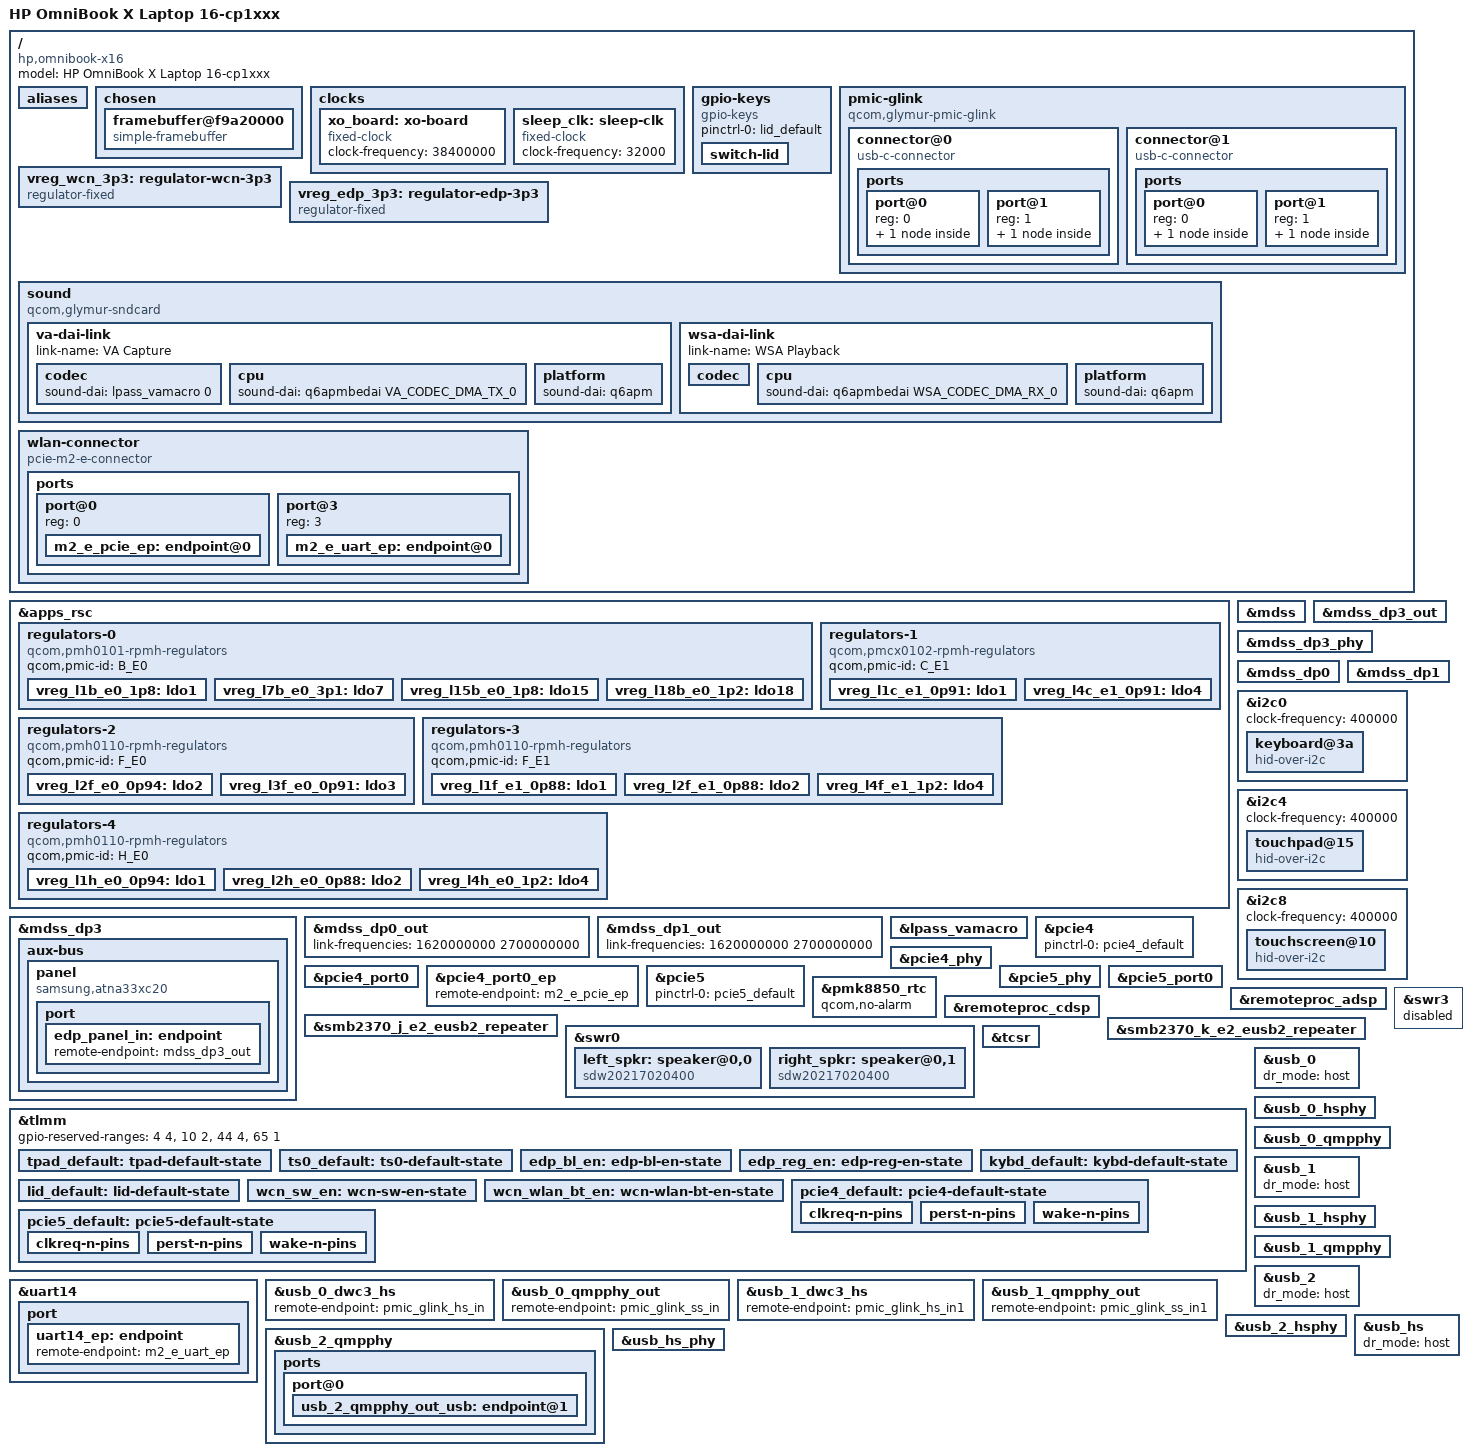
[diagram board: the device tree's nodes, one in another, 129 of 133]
// SPDX-License-Identifier: BSD-3-Clause
/*
 * HP OmniBook X Laptop 16-cp1xxx (Snapdragon X2 Elite, 12-core "Mahua")
 *
 * Community test device tree, built up in stages and boot-tested on one
 * laptop (board 8F46). Most hardware works; see the notes at the end and the
 * "Stage N" comments for what each block does and how it was verified.
 *
 * Derived from glymur-hp-elitebook-x-g2q.dts (board wiring) on top of
 * mahua.dtsi (SoC), following how mahua-crd.dts adapts Glymur to Mahua.
 *
 * Markers:
 *   VERIFIED   - confirmed from this laptop's ACPI tables or by a test boot
 *   DONOR      - copied from the EliteBook X G2q, NOT verified on this laptop
 *   GUESS      - best effort
 *   TODO       - unknown, must be found before it can be enabled
 */

/dts-v1/;

#include "mahua.dtsi"

#include "pmcx0102.dtsi"
#include "pmh0101.dtsi"
#include "pmh0110-glymur.dtsi"
#include "pmh0104-glymur.dtsi"
#include "pmk8850.dtsi"
#include "smb2370.dtsi"

#include <dt-bindings/gpio/gpio.h>
#include <dt-bindings/input/gpio-keys.h>
#include <dt-bindings/input/input.h>
#include <dt-bindings/interrupt-controller/irq.h>
#include <dt-bindings/regulator/qcom,rpmh-regulator.h>
#include <dt-bindings/sound/qcom,q6dsp-lpass-ports.h>

/* Same PMIC removals that mahua-crd.dts makes for the 12-core part */
/delete-node/ &pmcx0102_d_e0;
/delete-node/ &pmcx0102_d0_thermal;
/delete-node/ &pmh0104_i_e0;
/delete-node/ &pmh0104_i0_thermal;
/delete-node/ &pmh0104_j_e0;
/delete-node/ &pmh0104_j0_thermal;

/ {
	model = "HP OmniBook X Laptop 16-cp1xxx";
	compatible = "hp,omnibook-x16", "qcom,mahua";

	aliases {
		i2c0 = &i2c0;
		i2c4 = &i2c4;
		i2c8 = &i2c8;

		serial0 = &uart21;	/* debug UART, as on the other Glymur/Mahua laptops; fixes "Invalid line -19" */
		serial1 = &uart14;	/* DONOR; geni UART refuses to probe without an alias */
	};

	/*
	 * UEFI framebuffer, described here so simpledrm holds the display's
	 * power rails. Without a consumer, rpmhpd drops MMCX/MXC at sync_state
	 * and the screen goes black (theory from test boots 2 and 3, Oct 19).
	 * reg/width/height/stride VERIFIED from BOOTFB in /proc/iomem and
	 * /sys/class/graphics/fb0 in ACPI mode (1920x1200, stride 7680).
	 * Rail levels (nom) are a GUESS; supplies are the DONOR eDP PHY supplies.
	 * A /chosen framebuffer also stops sysfb from registering a second one.
	 */
	chosen {
		#address-cells = <2>;
		#size-cells = <2>;
		ranges;

		framebuffer@f9a20000 {
			compatible = "simple-framebuffer";
			reg = <0x0 0xf9a20000 0x0 0x8ca000>;
			width = <1920>;
			height = <1200>;
			stride = <(1920 * 4)>;
			format = "x8r8g8b8";

			power-domains = <&rpmhpd RPMHPD_MMCX>,
					<&rpmhpd RPMHPD_MXC>;
			required-opps = <&rpmhpd_opp_nom>,
					<&rpmhpd_opp_nom>;

			vdda-phy-supply = <&vreg_l2f_e1_0p88>;
			vdda-pll-supply = <&vreg_l4f_e1_1p2>;
		};
	};

	clocks {
		xo_board: xo-board {
			compatible = "fixed-clock";
			clock-frequency = <38400000>;
			#clock-cells = <0>;
		};

		sleep_clk: sleep-clk {
			compatible = "fixed-clock";
			clock-frequency = <32000>;
			#clock-cells = <0>;
		};
	};

	/* VERIFIED: ACPI LIDR uses TLMM pin 92 (0x5C), same as the donor */
	gpio-keys {
		compatible = "gpio-keys";

		pinctrl-0 = <&lid_default>;
		pinctrl-names = "default";

		switch-lid {
			label = "lid";
			gpios = <&tlmm 92 GPIO_ACTIVE_LOW>;
			linux,input-type = <EV_SW>;
			linux,code = <SW_LID>;
			wakeup-source;
			wakeup-event-action = <EV_ACT_DEASSERTED>;
		};
	};

	/*
	 * Stage 4. On Glymur/Mahua pmic-glink talks to the SoCCP (not the ADSP).
	 * VERIFIED: the PMIC_RTR_SOCCP_APPS rpmsg channel exists in DT mode, and
	 * the DSDT has PMGK (QCOM0F8E). Node layout DONOR.
	 * GUESS: firmware connector 0 = usb_0 (left back), 1 = usb_1 (left front),
	 * same order as the DSDT URS0/URS1.
	 */
	pmic-glink {
		compatible = "qcom,glymur-pmic-glink",
			     "qcom,pmic-glink";
		#address-cells = <1>;
		#size-cells = <0>;

		/* Left back port (usb_0) */
		connector@0 {
			compatible = "usb-c-connector";
			reg = <0>;
			power-role = "dual";
			data-role = "dual";

			ports {
				#address-cells = <1>;
				#size-cells = <0>;

				port@0 {
					reg = <0>;

					pmic_glink_hs_in: endpoint {
						remote-endpoint = <&usb_0_dwc3_hs>;
					};
				};

				port@1 {
					reg = <1>;

					pmic_glink_ss_in: endpoint {
						remote-endpoint = <&usb_0_qmpphy_out>;
					};
				};
			};
		};

		/* Left front port (usb_1) */
		connector@1 {
			compatible = "usb-c-connector";
			reg = <1>;
			power-role = "dual";
			data-role = "dual";

			ports {
				#address-cells = <1>;
				#size-cells = <0>;

				port@0 {
					reg = <0>;

					pmic_glink_hs_in1: endpoint {
						remote-endpoint = <&usb_1_dwc3_hs>;
					};
				};

				port@1 {
					reg = <1>;

					pmic_glink_ss_in1: endpoint {
						remote-endpoint = <&usb_1_qmpphy_out>;
					};
				};
			};
		};
	};

	/*
	 * Wi-Fi (QCC2072, PCI 17cb:1112). DONOR pins: all five Glymur boards
	 * in-tree agree on gpio94 (3.3 V switch) and gpio116/117 (BT/WLAN
	 * enable). The ACPI tables do not switch any Wi-Fi power. There is no
	 * pwrseq driver for the QCC2072, so it is described as an M.2 key E
	 * slot, like the Zenbook A16. Bluetooth (port@3 -> uart14) is left
	 * out for now.
	 */
	vreg_wcn_3p3: regulator-wcn-3p3 {
		compatible = "regulator-fixed";

		regulator-name = "VREG_WCN_3P3";
		regulator-min-microvolt = <3300000>;
		regulator-max-microvolt = <3300000>;

		gpio = <&tlmm 94 GPIO_ACTIVE_HIGH>;	/* DONOR */
		enable-active-high;

		pinctrl-0 = <&wcn_sw_en>;
		pinctrl-names = "default";

		regulator-boot-on;
	};

	/*
	 * Panel 3.3 V switch. DONOR: gpio70 on all five Glymur/Mahua boards
	 * upstream (CRD, EliteBook X G2q, Yoga Slim 7x, Zenbook A14/A16).
	 */
	vreg_edp_3p3: regulator-edp-3p3 {
		compatible = "regulator-fixed";

		regulator-name = "VREG_EDP_3P3";
		regulator-min-microvolt = <3300000>;
		regulator-max-microvolt = <3300000>;

		gpio = <&tlmm 70 GPIO_ACTIVE_HIGH>;	/* DONOR */
		enable-active-high;

		pinctrl-0 = <&edp_reg_en>;
		pinctrl-names = "default";

		regulator-boot-on;
	};

	/*
	 * Speakers + built-in mics, copied from the donor (DONOR). ACPI only
	 * describes the headphone jack (a Qualcomm SDCA codec, vendor 0x0217),
	 * so the speaker/mic wiring here is NOT verified for this board.
	 * model = "GLYMUR-CRD" (TEMP) so the kernel loads the installed
	 * qcom/glymur/GLYMUR-CRD-tplg.bin and ALSA uses the GLYMUR-CRD UCM.
	 * Both expect exactly these two links (WSA RX0 + VA TX0).
	 * Stage 8c: only TWO speakers (both on swr0, GUESS from boots 13-15 +
	 * Windows 2-ch endpoint + spec sites). ALSA must use a two-speaker UCM
	 * (/usr/share/alsa/ucm2/conf.d/glymur/HP-...-8F46.conf), not GLYMUR-CRD.
	 */
	sound {
		compatible = "qcom,glymur-sndcard";
		model = "GLYMUR-CRD";

		audio-routing = "SpkrLeft IN", "WSA WSA_SPK1 OUT",
				"SpkrRight IN", "WSA WSA_SPK2 OUT",
				"VA DMIC0", "vdd-micb",
				"VA DMIC1", "vdd-micb";

		va-dai-link {
			link-name = "VA Capture";

			codec {
				sound-dai = <&lpass_vamacro 0>;
			};

			cpu {
				sound-dai = <&q6apmbedai VA_CODEC_DMA_TX_0>;
			};

			platform {
				sound-dai = <&q6apm>;
			};
		};

		wsa-dai-link {
			link-name = "WSA Playback";

			codec {
				sound-dai = <&left_spkr>, <&right_spkr>,
					    <&swr0 0>, <&lpass_wsamacro 0>;
			};

			cpu {
				sound-dai = <&q6apmbedai WSA_CODEC_DMA_RX_0>;
			};

			platform {
				sound-dai = <&q6apm>;
			};
		};
	};

	wlan-connector {
		compatible = "pcie-m2-e-connector";
		vpcie3v3-supply = <&vreg_wcn_3p3>;
		vpcie1v8-supply = <&vreg_l15b_e0_1p8>;	/* DONOR */

		w-disable1-gpios = <&tlmm 117 GPIO_ACTIVE_LOW>;	/* DONOR (WLAN) */
		w-disable2-gpios = <&tlmm 116 GPIO_ACTIVE_LOW>;	/* DONOR (BT) */

		pinctrl-0 = <&wcn_wlan_bt_en>;
		pinctrl-names = "default";

		ports {
			#address-cells = <1>;
			#size-cells = <0>;

			port@0 {
				reg = <0>;
				#address-cells = <1>;
				#size-cells = <0>;

				m2_e_pcie_ep: endpoint@0 {
					reg = <0>;
					remote-endpoint = <&pcie4_port0_ep>;
				};
			};

			/*
			 * Bluetooth UART. VERIFIED from ACPI: BTH0 (QCOM0F6B) sits on
			 * UR15 = 0x00a98000 = uart14, 115200 baud + RTS/CTS, enable
			 * GPIO 0x74 = 116 (= w-disable2 above). Needs patched
			 * pwrseq-pcie-m2 + hci_qca (QCC2072 not upstream in 7.3).
			 */
			port@3 {
				reg = <3>;
				#address-cells = <1>;
				#size-cells = <0>;

				m2_e_uart_ep: endpoint@0 {
					reg = <0>;
					remote-endpoint = <&uart14_ep>;
				};
			};
		};
	};
};

&apps_rsc {
	/* DONOR: PMIC regulators, needed by the PCIe PHY and USB PHYs */
	regulators-0 {
		compatible = "qcom,pmh0101-rpmh-regulators";
		qcom,pmic-id = "B_E0";

		vreg_l1b_e0_1p8: ldo1 {
			regulator-name = "vreg_l1b_e0_1p8";
			regulator-min-microvolt = <1800000>;
			regulator-max-microvolt = <1800000>;
			regulator-initial-mode = <RPMH_REGULATOR_MODE_HPM>;
		};

		vreg_l7b_e0_3p1: ldo7 {
			regulator-name = "vreg_l7b_e0_3p1";
			regulator-min-microvolt = <3072000>;
			regulator-max-microvolt = <3072000>;
			regulator-initial-mode = <RPMH_REGULATOR_MODE_HPM>;
		};

		vreg_l15b_e0_1p8: ldo15 {
			regulator-name = "vreg_l15b_e0_1p8";
			regulator-min-microvolt = <1800000>;
			regulator-max-microvolt = <1800000>;
			regulator-initial-mode = <RPMH_REGULATOR_MODE_HPM>;
		};

		vreg_l18b_e0_1p2: ldo18 {
			regulator-name = "vreg_l18b_e0_1p2";
			regulator-min-microvolt = <1200000>;
			regulator-max-microvolt = <1200000>;
			regulator-initial-mode = <RPMH_REGULATOR_MODE_HPM>;
		};
	};

	regulators-1 {
		compatible = "qcom,pmcx0102-rpmh-regulators";
		qcom,pmic-id = "C_E1";

		vreg_l1c_e1_0p91: ldo1 {
			regulator-name = "vreg_l1c_e1_0p91";
			regulator-min-microvolt = <912000>;
			regulator-max-microvolt = <912000>;
			regulator-initial-mode = <RPMH_REGULATOR_MODE_HPM>;
		};

		/*
		 * Stage 10: usb_2 (USB-A) PHY rail. VERIFIED in this laptop's DSDT PEP
		 * package for \_SB.USB2 (PPP_RESOURCE_ID_LDO4_C_E1). Voltage DONOR from
		 * the Yoga Slim 7x / Zenbook A16 (912 mV; GLYMUR-CRD names it 0p72 but
		 * also names l3f_e0 0p72, which the HP donor runs at 912 mV).
		 */
		vreg_l4c_e1_0p91: ldo4 {
			regulator-name = "vreg_l4c_e1_0p91";
			regulator-min-microvolt = <912000>;
			regulator-max-microvolt = <912000>;
			regulator-initial-mode = <RPMH_REGULATOR_MODE_HPM>;
		};
	};

	regulators-2 {
		compatible = "qcom,pmh0110-rpmh-regulators";
		qcom,pmic-id = "F_E0";

		vreg_l2f_e0_0p94: ldo2 {
			regulator-name = "vreg_l2f_e0_0p94";
			regulator-min-microvolt = <936000>;
			regulator-max-microvolt = <936000>;
			regulator-initial-mode = <RPMH_REGULATOR_MODE_HPM>;
		};

		vreg_l3f_e0_0p91: ldo3 {
			regulator-name = "vreg_l3f_e0_0p91";
			regulator-min-microvolt = <912000>;
			regulator-max-microvolt = <912000>;
			regulator-initial-mode = <RPMH_REGULATOR_MODE_HPM>;
		};
	};

	regulators-3 {
		compatible = "qcom,pmh0110-rpmh-regulators";
		qcom,pmic-id = "F_E1";

		vreg_l1f_e1_0p88: ldo1 {
			regulator-name = "vreg_l1f_e1_0p88";
			regulator-min-microvolt = <880000>;
			regulator-max-microvolt = <880000>;
			regulator-initial-mode = <RPMH_REGULATOR_MODE_HPM>;
		};

		vreg_l2f_e1_0p88: ldo2 {
			regulator-name = "vreg_l2f_e1_0p88";
			regulator-min-microvolt = <880000>;
			regulator-max-microvolt = <880000>;
			regulator-initial-mode = <RPMH_REGULATOR_MODE_HPM>;
		};

		vreg_l4f_e1_1p2: ldo4 {
			regulator-name = "vreg_l4f_e1_1p2";
			regulator-min-microvolt = <1200000>;
			regulator-max-microvolt = <1200000>;
			regulator-initial-mode = <RPMH_REGULATOR_MODE_HPM>;
		};
	};

	regulators-4 {
		compatible = "qcom,pmh0110-rpmh-regulators";
		qcom,pmic-id = "H_E0";

		vreg_l1h_e0_0p94: ldo1 {
			regulator-name = "vreg_l1h_e0_0p94";
			regulator-min-microvolt = <936000>;
			regulator-max-microvolt = <936000>;
			regulator-initial-mode = <RPMH_REGULATOR_MODE_HPM>;
		};

		vreg_l2h_e0_0p88: ldo2 {
			regulator-name = "vreg_l2h_e0_0p88";
			regulator-min-microvolt = <880000>;
			regulator-max-microvolt = <880000>;
			regulator-initial-mode = <RPMH_REGULATOR_MODE_HPM>;
		};

		vreg_l4h_e0_1p2: ldo4 {
			regulator-name = "vreg_l4h_e0_1p2";
			regulator-min-microvolt = <1200000>;
			regulator-max-microvolt = <1200000>;
			regulator-initial-mode = <RPMH_REGULATOR_MODE_HPM>;
		};
	};
};

/*
 * Stage 11: display driver (msm DRM) on the internal eDP panel (DP3).
 * dispcc is enabled again (it is on by default in glymur.dtsi; stages 1-10
 * had it disabled). The /chosen simple-framebuffer stays as a fallback:
 * msm removes it when it takes over, simpledrm keeps working if msm fails.
 * USB-C DisplayPort (mdss_dp0/dp1) is added in stage 15 (below &mdss_dp3_phy).
 *
 * Panel: SDC 0x4214 OLED 1920x1200 (VERIFIED from Windows WmiMonitorID).
 * "samsung,atna33xc20" is the generic driver for Samsung OLED eDP panels
 * (backlight over DP AUX); the exact model name is unknown, so no specific
 * compatible. enable-gpios 18 / supply gpio70 = DONOR (all Glymur boards
 * agree). Link rates / 4 lanes = DONOR.
 */
&mdss {
	status = "okay";
};

&mdss_dp3 {
	/delete-property/ #sound-dai-cells;

	status = "okay";

	aux-bus {
		panel {
			compatible = "samsung,atna33xc20";	/* GUESS: generic */
			enable-gpios = <&tlmm 18 GPIO_ACTIVE_HIGH>;	/* DONOR */
			power-supply = <&vreg_edp_3p3>;

			pinctrl-0 = <&edp_bl_en>;
			pinctrl-names = "default";

			port {
				edp_panel_in: endpoint {
					remote-endpoint = <&mdss_dp3_out>;
				};
			};
		};
	};
};

&mdss_dp3_out {
	data-lanes = <0 1 2 3>;
	link-frequencies = /bits/ 64 <1620000000 2700000000 5400000000 8100000000>;

	remote-endpoint = <&edp_panel_in>;
};

&mdss_dp3_phy {
	vdda-phy-supply = <&vreg_l2f_e1_0p88>;
	vdda-pll-supply = <&vreg_l4f_e1_1p2>;

	status = "okay";
};

/*
 * Stage 15: DisplayPort alt mode on the two USB-C ports. DONOR (EliteBook X
 * G2q): glymur.dtsi already wires mdss_dp0 -> usb_0_qmpphy (left back) and
 * mdss_dp1 -> usb_1_qmpphy (left front); pmic_glink_altmode reports HPD and
 * the pin assignment through the connectors. Link rates DONOR. Whether HP
 * wired DP to these ports is not checked from ACPI, but both ports give a 1080p60
 * picture through a USB-C hub with HDMI output (VERIFIED).
 * At HBR2 (5.4 Gbps) link training passed but the stream ran at exactly 30 Hz
 * instead of 60 (measured vblanks) -> no picture. Capped at HBR (2.7 Gbps): 60 Hz,
 * picture OK (VERIFIED). Likely cause: the QMP v8 VCO_DIV value for 5400 in
 * phy-qcom-qmp-combo.c (0x4; the Glymur eDP PHY uses 0x2). Remove the cap once
 * that is fixed. With the cap: 2 lanes x HBR, enough for 1080p60, not 1440p60/4K60.
 */
&mdss_dp0 {
	status = "okay";
};

&mdss_dp0_out {
	link-frequencies = /bits/ 64 <1620000000 2700000000>; /* HBR max: HBR2 runs at half rate, see above */
};

&mdss_dp1 {
	status = "okay";
};

&mdss_dp1_out {
	link-frequencies = /bits/ 64 <1620000000 2700000000>; /* HBR max: HBR2 runs at half rate, see above */
};

/*
 * Keyboard: bus i2c@b80000, address 0x3a and HID descriptor address 1 are
 * VERIFIED from this laptop's DSDT (QTEC0001 on ACPI I2C1, 400 kHz).
 * Interrupt gpio67 (from the donor) is VERIFIED by test boot 3 (Oct 19):
 * typing blind at the tty1 login prompt produced login attempts in auth.log.
 */
/*
 * GPU/GMU: left enabled (glymur.dtsi has no status). With the stock 7.3 kernel the
 * screen is corrupted under hardware rendering: msm reports the full 4-slice GMEM, but
 * Mahua's X2-85 has 3 slices. FIX VERIFIED (Oct 22): "drm/msm: Mahua GPU support" v1.
 * Patch 5 goes into mahua.dtsi (gpu "qcom,adreno-44060000", gmu "qcom,adreno-gmu-x285.0")
 * and REQUIRES a msm.ko with patch 3 (catalog entry 0x44060000, 15.75 MB GMEM); with the
 * stock msm.ko that DTB has no GPU. Without either patch, the Mesa workaround (FD_MESA_DEBUG/
 * TU_DEBUG=sysmem, VERIFIED boot 22) avoids the corruption. See gpu/ in the repo.
 */

&i2c0 {
	clock-frequency = <400000>;

	status = "okay";

	keyboard@3a {
		compatible = "hid-over-i2c";
		reg = <0x3a>;

		hid-descr-addr = <0x1>;
		interrupts-extended = <&tlmm 67 IRQ_TYPE_LEVEL_LOW>; /* VERIFIED */

		pinctrl-0 = <&kybd_default>;
		pinctrl-names = "default";

		wakeup-source;
	};
};

/*
 * Touchpad: bus i2c@b90000, address 0x15 and HID descriptor address 1 are
 * VERIFIED (ELAN0189 on ACPI I2C5, 400 kHz). The interrupt pin is NOT
 * verified: ACPI says 896 in an undecoded numbering, but both the
 * x1-hp-omnibook-x14.dtsi and glymur-hp-elitebook-x-g2q.dts use gpio3 for
 * their touchpads (the X14 also uses address 0x15), so gpio3 is the guess.
 */
&i2c4 {
	clock-frequency = <400000>;

	status = "okay";

	touchpad@15 {
		compatible = "hid-over-i2c";
		reg = <0x15>;

		hid-descr-addr = <0x1>;
		interrupts-extended = <&tlmm 3 IRQ_TYPE_LEVEL_LOW>; /* GUESS */

		pinctrl-0 = <&tpad_default>;
		pinctrl-names = "default";

		wakeup-source;
	};
};

/*
 * Touchscreen (stage 14): ACPI TSC1 = ELAN2513 on I2C9 (QUP_1_SE_0, base
 * 0x00a80000 = i2c8), address 0x10, 400 kHz, HID descriptor address 1,
 * GpioInt pin 51 level active-low. VERIFIED from this laptop's DSDT (decoded
 * by hand); TSC1 _STA is on because \_SB.SKID = 1. Matches the donor node
 * exactly. VERIFIED Oct 21: ELAN 04F3:44BF probes on 8-0010 and touch works.
 */
&i2c8 {
	clock-frequency = <400000>;

	status = "okay";

	touchscreen@10 {
		compatible = "hid-over-i2c";
		reg = <0x10>;

		hid-descr-addr = <0x1>;
		interrupts-extended = <&tlmm 51 IRQ_TYPE_LEVEL_LOW>;

		post-power-on-delay-ms = <200>;	/* DONOR */

		pinctrl-0 = <&ts0_default>;
		pinctrl-names = "default";
	};
};

/* Built-in digital mics on DMIC0/1 (DONOR) */
&lpass_vamacro {
	vdd-micb-supply = <&vreg_l1b_e0_1p8>;

	pinctrl-0 = <&dmic01_default>;
	pinctrl-names = "default";

	qcom,dmic-sample-rate = <4800000>;
};

/* Wi-Fi (ACPI shows it on PCIe domain 4, matching the donors' pcie4) */
&pcie4 {
	pinctrl-0 = <&pcie4_default>;
	pinctrl-names = "default";

	status = "okay";
};

&pcie4_phy {
	vdda-phy-supply = <&vreg_l1c_e1_0p91>;	/* DONOR */
	vdda-pll-supply = <&vreg_l4f_e1_1p2>;	/* DONOR */

	status = "okay";
};

&pcie4_port0 {
	reset-gpios = <&tlmm 146 GPIO_ACTIVE_LOW>;	/* DONOR */
	wake-gpios = <&tlmm 148 GPIO_ACTIVE_LOW>;	/* DONOR */
};

&pcie4_port0_ep {
	remote-endpoint = <&m2_e_pcie_ep>;
};

/* NVMe (ACPI shows the SSD on PCIe domain 5, matching the donor's pcie5) */
&pcie5 {
	/*
	 * TODO: the donor powers the SSD through vreg_nvme (PMIC gpio14).
	 * Omitted in stage 1 because firmware already powered it; add it if
	 * the SSD does not enumerate.
	 */
	pinctrl-0 = <&pcie5_default>;
	pinctrl-names = "default";

	status = "okay";
};

&pcie5_phy {
	vdda-phy-supply = <&vreg_l2f_e0_0p94>;
	vdda-pll-supply = <&vreg_l4h_e0_1p2>;

	status = "okay";
};

&pcie5_port0 {
	reset-gpios = <&tlmm 152 GPIO_ACTIVE_LOW>;	/* DONOR */
	wake-gpios = <&tlmm 154 GPIO_ACTIVE_LOW>;	/* DONOR */

	status = "okay";
};

&pmk8850_rtc {
	qcom,no-alarm;
	/*
	 * No qcom,uefi-rtc-info: this machine has no RTCInfo UEFI variable, so the
	 * driver failed with -ENOENT. Without it rtc0 registers read-only with
	 * offset 0 (suggested by Konrad Dybcio on linux-arm-msm, Oct 22 2026).
	 * VERIFIED Oct 22: probes, but reads the raw PMIC counter (~1970), not
	 * real time. NTP still sets the clock.
	 */
};

/* DONOR: eUSB2 repeaters for USB-C ports 0 and 1 */
&remoteproc_adsp {
	/*
	 * Stage 3. Firmware VERIFIED present in this laptop's Windows driver store
	 * (qcsubsys_ext_adsp8480), HP-signed (differs from linux-firmware's
	 * generic glymur adsp.mbn). Installed to /lib/firmware/qcom/mahua/hp/omnibook-x16/.
	 * Node layout DONOR. (pmic-glink does not need the ADSP; it uses the SoCCP.)
	 */
	firmware-name = "qcom/mahua/hp/omnibook-x16/qcadsp8480.mbn",
			"qcom/mahua/hp/omnibook-x16/adsp_dtbs.elf";

	status = "okay";
};

&remoteproc_cdsp {
	/* Stage 3. Firmware VERIFIED from Windows (qcnspmcdm8480). Node DONOR. */
	firmware-name = "qcom/mahua/hp/omnibook-x16/qccdsp8480.mbn",
			"qcom/mahua/hp/omnibook-x16/cdsp_dtbs.elf";

	status = "okay";
};

&smb2370_j_e2_eusb2_repeater {
	vdd18-supply = <&vreg_l15b_e0_1p8>;
	vdd3-supply = <&vreg_l7b_e0_3p1>;
};

&smb2370_k_e2_eusb2_repeater {
	vdd18-supply = <&vreg_l15b_e0_1p8>;
	vdd3-supply = <&vreg_l7b_e0_3p1>;
};

/*
 * Stage 10: eUSB2 repeater for usb_2 (USB-A). smb2370_l at SPMI2 SID 0xb was a
 * GUESS and is WRONG: boot 17 "pmic-spmi 2-0b: probe ... failed with error -5"
 * (SPMI transaction failed = no chip at that SID), so usb_2_hsphy deferred
 * forever. Left disabled. Where the USB-A repeater sits (if any) is unknown.
 */

/*
 * Speaker amps: 2x WSA8845 on swr0. Reset pin LPASS 12 VERIFIED (Windows AUCD
 * _CRS). Port maps DONOR. Amp 0,0 = left, 0,1 = right (user listening test,
 * boots 13/15: 4-ch "Front Left" -> 0,0 from the left, "Rear Left" -> 0,1 from
 * the right). The donor's 4-amp layout (swr3 with 2 more amps) does not match:
 * nothing ever answered on swr3 (boots 12-15).
 */
&swr0 {
	status = "okay";

	/* WSA8845, left speaker */
	left_spkr: speaker@0,0 {
		compatible = "sdw20217020400";
		reg = <0 0>;
		reset-gpios = <&lpass_tlmm 12 GPIO_ACTIVE_LOW>;
		#sound-dai-cells = <0>;
		sound-name-prefix = "SpkrLeft";
		vdd-1p8-supply = <&vreg_l15b_e0_1p8>;
		vdd-io-supply = <&vreg_l18b_e0_1p2>;
		qcom,port-mapping = <1 2 3 7 12 14>;
	};

	/* WSA8845, right speaker */
	right_spkr: speaker@0,1 {
		compatible = "sdw20217020400";
		reg = <0 1>;
		reset-gpios = <&lpass_tlmm 12 GPIO_ACTIVE_LOW>;
		#sound-dai-cells = <0>;
		sound-name-prefix = "SpkrRight";
		vdd-1p8-supply = <&vreg_l15b_e0_1p8>;
		vdd-io-supply = <&vreg_l18b_e0_1p2>;
		qcom,port-mapping = <4 5 6 7 13 15>;
	};
};

&swr3 {
	/* No amps on this bus on this board (see &swr0). */
	status = "disabled";
};

/*
 * Best-effort mapping of the Mahua CRD's QREF supplies onto the regulators
 * this board has (matched by PMIC rail, voltages differ). Unverified.
 */
&tcsr {
	vdda-qrefrpt0-0p9-supply = <&vreg_l2f_e1_0p88>;
	vdda-qrefrpt1-0p9-supply = <&vreg_l2f_e1_0p88>;
	vdda-qrefrpt2-0p9-supply = <&vreg_l2f_e1_0p88>;
	vdda-qrefrpt3-0p9-supply = <&vreg_l1f_e1_0p88>;
	vdda-qrefrpt4-0p9-supply = <&vreg_l2h_e0_0p88>;
	vdda-qrefrpt5-0p9-supply = <&vreg_l2h_e0_0p88>;
	vdda-qrefrx0-0p9-supply = <&vreg_l2f_e1_0p88>;
	vdda-qrefrx1-0p9-supply = <&vreg_l2f_e1_0p88>;
	vdda-qrefrx2-0p9-supply = <&vreg_l2f_e1_0p88>;
	vdda-qrefrx3-0p9-supply = <&vreg_l2h_e0_0p88>;
	vdda-qreftx1-0p9-supply = <&vreg_l1f_e1_0p88>;
	vdda-refgen3-0p9-supply = <&vreg_l1f_e1_0p88>;
	vdda-refgen3-1p2-supply = <&vreg_l4f_e1_1p2>;
};

&tlmm {
	/* DONOR: pins owned by secure world / EC; may differ on this board */
	gpio-reserved-ranges = <4 4>, /* EC TZ Secure I3C */
			       <10 2>, /* OOB UART */
			       <44 4>, /* Security SPI (TPM) */
			       <65 1>; /* EC reset */

	tpad_default: tpad-default-state {
		pins = "gpio3";
		function = "gpio";
		bias-disable;
	};

	/* ACPI asks for PullUp on this pin; the donor uses bias-disable */
	ts0_default: ts0-default-state {
		pins = "gpio51";
		function = "gpio";
		bias-disable;
	};

	edp_bl_en: edp-bl-en-state {
		pins = "gpio18";
		function = "gpio";
		drive-strength = <16>;
		bias-disable;
	};

	edp_reg_en: edp-reg-en-state {
		pins = "gpio70";
		function = "gpio";
		drive-strength = <16>;
		bias-disable;
	};

	kybd_default: kybd-default-state {
		pins = "gpio67";
		function = "gpio";
		bias-disable;
	};

	lid_default: lid-default-state {
		pins = "gpio92";
		function = "gpio";
		bias-disable;
	};

	wcn_sw_en: wcn-sw-en-state {
		pins = "gpio94";
		function = "gpio";
		drive-strength = <2>;
		bias-disable;
	};

	wcn_wlan_bt_en: wcn-wlan-bt-en-state {
		pins = "gpio116", "gpio117";
		function = "gpio";
		drive-strength = <2>;
		bias-disable;
	};

	pcie4_default: pcie4-default-state {
		clkreq-n-pins {
			pins = "gpio147";
			function = "pcie4_clk_req_n";
			drive-strength = <2>;
			bias-pull-up;
		};

		perst-n-pins {
			pins = "gpio146";
			function = "gpio";
			drive-strength = <2>;
			bias-disable;
		};

		wake-n-pins {
			pins = "gpio148";
			function = "gpio";
			drive-strength = <2>;
			bias-pull-up;
		};
	};

	pcie5_default: pcie5-default-state {
		clkreq-n-pins {
			pins = "gpio153";
			function = "pcie5_clk_req_n";
			drive-strength = <2>;
			bias-pull-up;
		};

		perst-n-pins {
			pins = "gpio152";
			function = "gpio";
			drive-strength = <2>;
			bias-disable;
		};

		wake-n-pins {
			pins = "gpio154";
			function = "gpio";
			drive-strength = <2>;
			bias-pull-up;
		};
	};
};

/*
 * Stage 2: USB-C ports 0 and 1, wiring and supplies DONOR.
 *
 * VERIFIED from the DSDT: URS0 (0x0a600000 = usb_0), URS1 (0x0a800000 =
 * usb_1), USB2 (0x0a000000 = usb_2) and USB4 (0x0a200000 = usb_hs) are
 * enabled; USB3 (0x0a400000 = usb_mp) returns _STA 0, so no usb_mp here.
 *
 * VERIFIED boot 6: without orientation info, SuperSpeed works with the plug
 * one way round only. Stage 4 adds pmic-glink (above) for orientation.
 * Ports stay forced to host mode for now (no role switch), so the hub
 * keeps working even if pmic-glink misbehaves. Role switching is a later step.
 */
&uart14 {
	status = "okay";

	/* The bluetooth child node is created at runtime by pwrseq-pcie-m2 */
	port {
		uart14_ep: endpoint {
			remote-endpoint = <&m2_e_uart_ep>;
		};
	};
};

&usb_0 {
	dr_mode = "host";
	/delete-property/ usb-role-switch;

	status = "okay";
};

&usb_0_dwc3_hs {
	remote-endpoint = <&pmic_glink_hs_in>;
};

&usb_0_hsphy {
	vdd-supply = <&vreg_l3f_e0_0p91>;
	vdda12-supply = <&vreg_l4h_e0_1p2>;

	phys = <&smb2370_j_e2_eusb2_repeater>;

	status = "okay";
};

&usb_0_qmpphy {
	vdda-phy-supply = <&vreg_l3f_e0_0p91>;
	vdda-pll-supply = <&vreg_l4h_e0_1p2>;
	refgen-supply = <&vreg_l2f_e0_0p94>;

	status = "okay";
};

&usb_0_qmpphy_out {
	remote-endpoint = <&pmic_glink_ss_in>;
};

&usb_1 {
	dr_mode = "host";
	/delete-property/ usb-role-switch;

	status = "okay";
};

&usb_1_dwc3_hs {
	remote-endpoint = <&pmic_glink_hs_in1>;
};

&usb_1_hsphy {
	vdd-supply = <&vreg_l3f_e0_0p91>;
	vdda12-supply = <&vreg_l4h_e0_1p2>;

	phys = <&smb2370_k_e2_eusb2_repeater>;

	status = "okay";
};

&usb_1_qmpphy {
	vdda-phy-supply = <&vreg_l1h_e0_0p94>;
	vdda-pll-supply = <&vreg_l4h_e0_1p2>;
	refgen-supply = <&vreg_l2f_e0_0p94>;

	status = "okay";
};

&usb_1_qmpphy_out {
	remote-endpoint = <&pmic_glink_ss_in1>;
};

/*
 * Stage 10: usb_2 = the single USB-A port (right side). VERIFIED from the DSDT:
 * USB2 (QCOM0F9A, 0x0a000000) RHUB ports use UPC3 = USB 3 Standard-A; user test
 * (boot 6): nothing enumerates there with usb_2 disabled. Not Type-C, so host
 * only, no pmic-glink, and no orientation/mode switching (like the Zenbook A14/
 * A16 usb_2_qmpphy). Supplies: all 5 rails are in the DSDT PEP package for USB2
 * (LDO4_C_E1, LDO4_F_E1, LDO1_C_E1 + the repeater's LDO15_B/LDO7_B); which
 * rail feeds which PHY input is DONOR (Zenbook A16 qmpphy, Yoga hsphy/refgen).
 */
&usb_2 {
	dr_mode = "host";
	/delete-property/ usb-role-switch;

	status = "okay";
};

&usb_2_hsphy {
	vdd-supply = <&vreg_l4c_e1_0p91>;
	vdda12-supply = <&vreg_l4f_e1_1p2>;

	/*
	 * Stage 10b: no repeater (optional in phy-qcom-m31-eusb2). TEST: relies on
	 * UEFI having left the real repeater set up, if there is one.
	 */

	status = "okay";
};

&usb_2_qmpphy {
	vdda-phy-supply = <&vreg_l4c_e1_0p91>;
	vdda-pll-supply = <&vreg_l4f_e1_1p2>;
	refgen-supply = <&vreg_l1c_e1_0p91>;

	/delete-property/ mode-switch;
	/delete-property/ orientation-switch;

	status = "okay";

	/*
	 * Static USB3-only lanes (<1 0> = USB3, normal orientation). Without them
	 * qmp_combo_probe() warns "unable to determine orientation & mode from
	 * data-lanes" and stays in USB3+DP mode. VERIFIED (Oct 24): warning gone,
	 * USB-A still works at 5000M and USB2.
	 */
	ports {
		port@0 {
			#address-cells = <1>;
			#size-cells = <0>;

			/delete-node/ endpoint;

			usb_2_qmpphy_out_usb: endpoint@1 {
				reg = <1>;

				data-lanes = <1 0>;
			};
		};
	};
};

/*
 * Stage 7: internal USB2 host for the webcam.
 * VERIFIED from the ACPI-mode kernel log: the controller at 0x0a200000
 * (QCOM0FEF = usb_hs) had "HP True Vision FHD Camera" (30c9:00d9, RGB + IR
 * UVC interfaces) on port 1. DSDT USB4 RHUB has RGCM/IRCM children.
 * Supplies and "no repeater" are DONOR (EliteBook X G2q uses it for its
 * fingerprint reader). usb-role-switch removed like usb_0/usb_1 (GUESS:
 * the donor keeps it, but nothing here would act as the role switch).
 */
&usb_hs {
	dr_mode = "host";
	/delete-property/ usb-role-switch;

	status = "okay";
};

&usb_hs_phy {
	vdd-supply = <&vreg_l2h_e0_0p88>;
	vdda12-supply = <&vreg_l4h_e0_1p2>;

	status = "okay";
};

/*
 * Deliberately NOT enabled yet (see the donor for the wiring):
 *   gpu/gmu        -> needs firmware extracted from Windows
 *   remoteproc_soccp -> already running from UEFI (attached), left alone
 *   bluetooth      -> uart14 + wlan-connector port@3, later
 *   headphone jack -> Qualcomm SDCA codec (ACPI QSJ0, vendor 0x0217), no
 *                     Linux driver/DT description yet
 */
